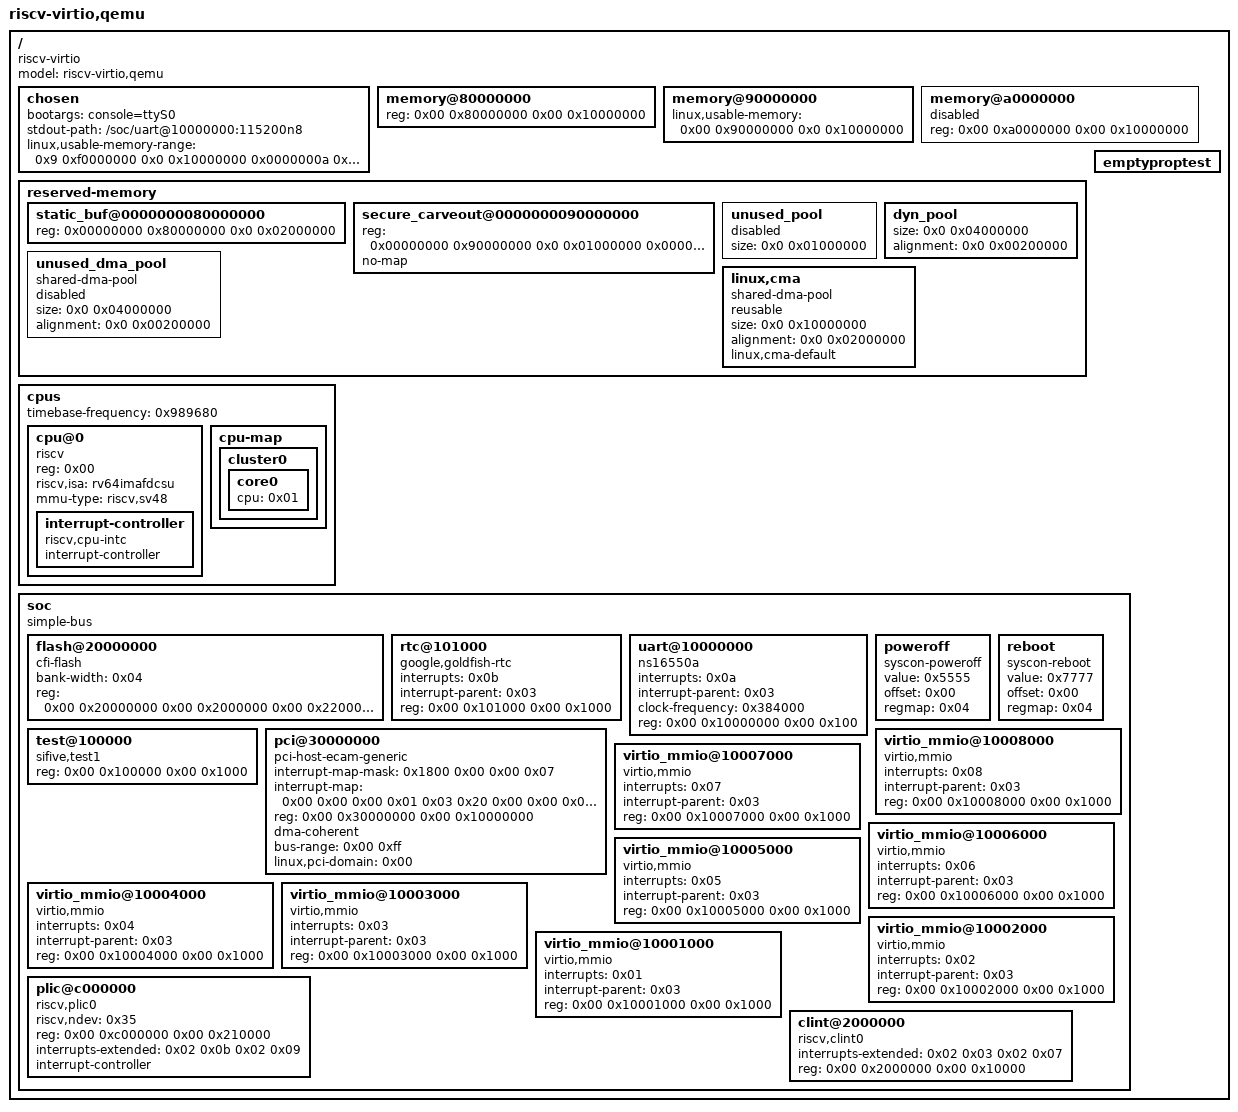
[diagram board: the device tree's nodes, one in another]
/dts-v1/;

/memreserve/ 0x0000000080000000 0x0000000001000000;  // 16 MiB
/memreserve/ 0x0000000090000000 0x0000000000100000;  // 1 MiB

/ {
	#address-cells = <0x02>;
	#size-cells = <0x02>;
	compatible = "riscv-virtio";
	model = "riscv-virtio,qemu";

	chosen {
		bootargs = "console=ttyS0";
		stdout-path = "/soc/uart@10000000:115200n8";
		linux,usable-memory-range = <0x9 0xf0000000 0x0 0x10000000 
		              0x0000000a 0x00000000  0x00000000 0x20000000>;
	};

	memory@80000000 {
		device_type = "memory";
		reg = <0x00 0x80000000 0x00 0x10000000>;
	};

	memory@90000000 {
		device_type = "memory";
		linux,usable-memory = <0x00 0x90000000 0x0 0x10000000>;
	};

	memory@a0000000 {
		device_type = "memory";
		reg = <0x00 0xa0000000 0x00 0x10000000>;
		status = "disabled";
	};

	reserved-memory {
		#address-cells = <2>;
		#size-cells = <2>;
		ranges;

		// linux valid normal reserved mem region
		static_buf@0000000080000000 {
			reg = <0x00000000 0x80000000   0x0 0x02000000>; // base=0x8000_0000, size=32MiB
		};

		secure_carveout@0000000090000000 {
			// two reg
			reg = <0x00000000 0x90000000   0x0 0x01000000 
			       0x00000000 0x91000000   0x0 0x01000000>;
			no-map;
		        status = "okay";
		};
		
		unused_pool {
		        size = <0x0 0x01000000>; // 16MiB
		        status = "disabled";     // should skip
		};

		dyn_pool {
		        // no reg
			size = <0x0 0x04000000>;      // 64MiB
			alignment = <0x0 0x00200000>; // 2MiB 对齐（可选）
		        status = "okay";
		};

		unused_dma_pool {
		        compatible = "shared-dma-pool";
		        size = <0x0 0x04000000>;      // 64MiB
		        alignment = <0x0 0x00200000>; // 2MiB 对齐（可选）
		        status = "disabled";          // should skip
		};

		linux,cma {
		        compatible = "shared-dma-pool";
		        reusable;
		        size = <0x0 0x10000000>;      // 256MiB
		        alignment = <0x0 0x02000000>; // 32MiB（示例，对齐可按需求设大页/设备限制）
		        linux,cma-default;            // 指定为默认 CMA
		        status = "okay";
		};


	};

	cpus {
		#address-cells = <0x01>;
		#size-cells = <0x00>;
		timebase-frequency = <0x989680>;

		cpu@0 {
			phandle = <0x01>;
			device_type = "cpu";
			reg = <0x00>;
			status = "okay";
			compatible = "riscv";
			riscv,isa = "rv64imafdcsu";
			mmu-type = "riscv,sv48";

			interrupt-controller {
				#interrupt-cells = <0x01>;
				interrupt-controller;
				compatible = "riscv,cpu-intc";
				phandle = <0x02>;
			};
		};

		cpu-map {

			cluster0 {

				core0 {
					cpu = <0x01>;
				};
			};
		};
	};

	emptyproptest {

	};

	soc {
		#address-cells = <0x02>;
		#size-cells = <0x02>;
		compatible = "simple-bus";
		ranges;

		flash@20000000 {
			bank-width = <0x04>;
			reg = <0x00 0x20000000 0x00 0x2000000 0x00 0x22000000 0x00 0x2000000>;
			compatible = "cfi-flash";
		};

		rtc@101000 {
			interrupts = <0x0b>;
			interrupt-parent = <0x03>;
			reg = <0x00 0x101000 0x00 0x1000>;
			compatible = "google,goldfish-rtc";
		};

		uart@10000000 {
			interrupts = <0x0a>;
			interrupt-parent = <0x03>;
			clock-frequency = <0x384000>;
			reg = <0x00 0x10000000 0x00 0x100>;
			compatible = "ns16550a";
		};

		poweroff {
			value = <0x5555>;
			offset = <0x00>;
			regmap = <0x04>;
			compatible = "syscon-poweroff";
		};

		reboot {
			value = <0x7777>;
			offset = <0x00>;
			regmap = <0x04>;
			compatible = "syscon-reboot";
		};

		test@100000 {
			phandle = <0x04>;
			reg = <0x00 0x100000 0x00 0x1000>;
			compatible = "sifive,test1\0sifive,test0\0syscon";
		};

		pci@30000000 {
			interrupt-map-mask = <0x1800 0x00 0x00 0x07>;
			interrupt-map = <0x00 0x00 0x00 0x01 0x03 0x20 0x00 0x00 0x00 0x02 0x03 0x21 0x00 0x00 0x00 0x03 0x03 0x22 0x00 0x00 0x00 0x04 0x03 0x23 0x800 0x00 0x00 0x01 0x03 0x21 0x800 0x00 0x00 0x02 0x03 0x22 0x800 0x00 0x00 0x03 0x03 0x23 0x800 0x00 0x00 0x04 0x03 0x20 0x1000 0x00 0x00 0x01 0x03 0x22 0x1000 0x00 0x00 0x02 0x03 0x23 0x1000 0x00 0x00 0x03 0x03 0x20 0x1000 0x00 0x00 0x04 0x03 0x21 0x1800 0x00 0x00 0x01 0x03 0x23 0x1800 0x00 0x00 0x02 0x03 0x20 0x1800 0x00 0x00 0x03 0x03 0x21 0x1800 0x00 0x00 0x04 0x03 0x22>;
			ranges = <0x1000000 0x00 0x00 0x00 0x3000000 0x00 0x10000 0x2000000 0x00 0x40000000 0x00 0x40000000 0x00 0x40000000>;
			reg = <0x00 0x30000000 0x00 0x10000000>;
			dma-coherent;
			bus-range = <0x00 0xff>;
			linux,pci-domain = <0x00>;
			device_type = "pci";
			compatible = "pci-host-ecam-generic";
			#size-cells = <0x02>;
			#interrupt-cells = <0x01>;
			#address-cells = <0x03>;
		};

		virtio_mmio@10008000 {
			interrupts = <0x08>;
			interrupt-parent = <0x03>;
			reg = <0x00 0x10008000 0x00 0x1000>;
			compatible = "virtio,mmio";
		};

		virtio_mmio@10007000 {
			interrupts = <0x07>;
			interrupt-parent = <0x03>;
			reg = <0x00 0x10007000 0x00 0x1000>;
			compatible = "virtio,mmio";
		};

		virtio_mmio@10006000 {
			interrupts = <0x06>;
			interrupt-parent = <0x03>;
			reg = <0x00 0x10006000 0x00 0x1000>;
			compatible = "virtio,mmio";
		};

		virtio_mmio@10005000 {
			interrupts = <0x05>;
			interrupt-parent = <0x03>;
			reg = <0x00 0x10005000 0x00 0x1000>;
			compatible = "virtio,mmio";
		};

		virtio_mmio@10004000 {
			interrupts = <0x04>;
			interrupt-parent = <0x03>;
			reg = <0x00 0x10004000 0x00 0x1000>;
			compatible = "virtio,mmio";
		};

		virtio_mmio@10003000 {
			interrupts = <0x03>;
			interrupt-parent = <0x03>;
			reg = <0x00 0x10003000 0x00 0x1000>;
			compatible = "virtio,mmio";
		};

		virtio_mmio@10002000 {
			interrupts = <0x02>;
			interrupt-parent = <0x03>;
			reg = <0x00 0x10002000 0x00 0x1000>;
			compatible = "virtio,mmio";
		};

		virtio_mmio@10001000 {
			interrupts = <0x01>;
			interrupt-parent = <0x03>;
			reg = <0x00 0x10001000 0x00 0x1000>;
			compatible = "virtio,mmio";
		};

		plic@c000000 {
			phandle = <0x03>;
			riscv,ndev = <0x35>;
			reg = <0x00 0xc000000 0x00 0x210000>;
			interrupts-extended = <0x02 0x0b 0x02 0x09>;
			interrupt-controller;
			compatible = "riscv,plic0";
			#interrupt-cells = <0x01>;
			#address-cells = <0x00>;
		};

		clint@2000000 {
			interrupts-extended = <0x02 0x03 0x02 0x07>;
			reg = <0x00 0x2000000 0x00 0x10000>;
			compatible = "riscv,clint0";
		};
	};
};
